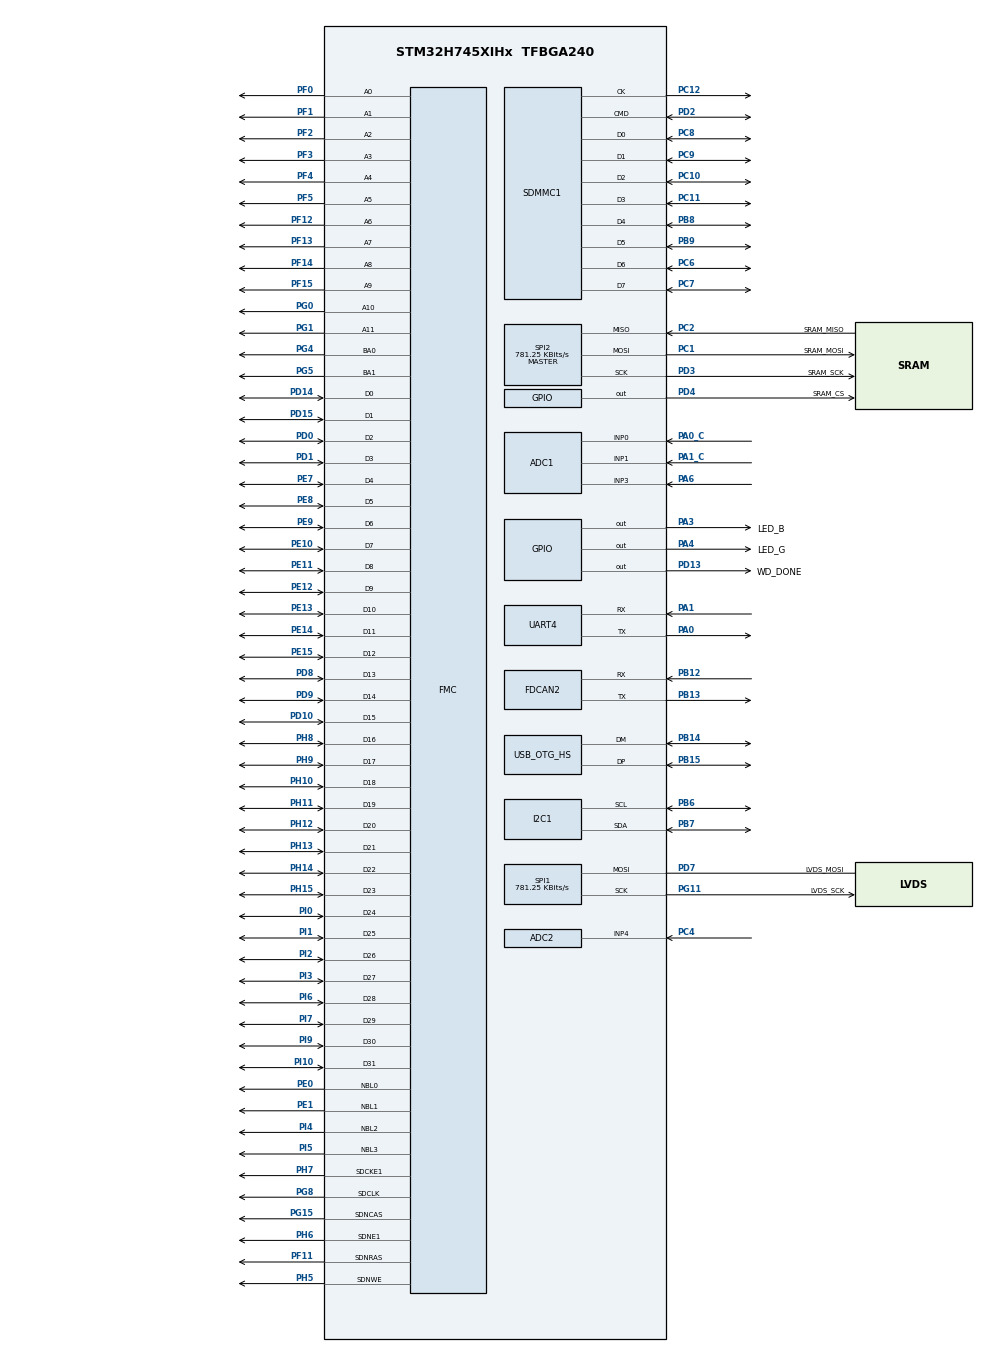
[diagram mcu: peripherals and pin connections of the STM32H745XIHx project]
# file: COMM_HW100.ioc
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ADC1.Channel-0\#ChannelRegularConversion=ADC_CHANNEL_0
ADC1.Channel-1\#ChannelRegularConversion=ADC_CHANNEL_1
ADC1.Channel-2\#ChannelRegularConversion=ADC_CHANNEL_3
ADC1.ContinuousConvMode=ENABLE
ADC1.NbrOfConversion=3
ADC1.NbrOfConversionFlag=1
ADC1.OffsetNumber-0\#ChannelRegularConversion=ADC_OFFSET_NONE
ADC1.OffsetNumber-1\#ChannelRegularConversion=ADC_OFFSET_NONE
ADC1.OffsetNumber-2\#ChannelRegularConversion=ADC_OFFSET_NONE
ADC1.OffsetSignedSaturation-0\#ChannelRegularConversion=DISABLE
ADC1.OffsetSignedSaturation-1\#ChannelRegularConversion=DISABLE
ADC1.OffsetSignedSaturation-2\#ChannelRegularConversion=DISABLE
ADC1.Overrun=ADC_OVR_DATA_OVERWRITTEN
ADC1.Rank-0\#ChannelRegularConversion=1
ADC1.Rank-1\#ChannelRegularConversion=2
ADC1.Rank-2\#ChannelRegularConversion=3
ADC1.SamplingTime-0\#ChannelRegularConversion=ADC_SAMPLETIME_1CYCLE_5
ADC1.SamplingTime-1\#ChannelRegularConversion=ADC_SAMPLETIME_1CYCLE_5
ADC1.SamplingTime-2\#ChannelRegularConversion=ADC_SAMPLETIME_1CYCLE_5
ADC1.master=1
ADC2.Channel-0\#ChannelRegularConversion=ADC_CHANNEL_4
ADC2.ContinuousConvMode=ENABLE
ADC2.NbrOfConversionFlag=1
ADC2.OffsetNumber-0\#ChannelRegularConversion=ADC_OFFSET_NONE
ADC2.OffsetSignedSaturation-0\#ChannelRegularConversion=DISABLE
ADC2.Overrun=ADC_OVR_DATA_OVERWRITTEN
ADC2.Rank-0\#ChannelRegularConversion=1
ADC2.SamplingTime-0\#ChannelRegularConversion=ADC_SAMPLETIME_1CYCLE_5
CORTEX_M7.Enable_Spec=__NULL
CORTEX_M7.MPU_Control=__NULL
CORTEX_M7.default_mode_Activation=1
CortexM4.IPs=BDMA,CORTEX_M4\:I,DMA,FATFS_M4\:I,FREERTOS_M4\:I,GPIO,IWDG2\:I,MDMA,NVIC2\:I,OPENAMP_M4\:I,PDM2PCM_M4\:I,PWR,RCC,RESMGR_UTILITY,SYS_M4\:I,USB_DEVICE_M4\:I,USB_HOST_M4\:I,VREFBUF,WWDG2\:I,DEBUG,FMC\:I
CortexM4.Pins=PD4
CortexM7.IPs=BDMA\:I,CORTEX_M7\:I,DMA\:I,FATFS_M7\:I,FREERTOS_M7\:I,GPIO\:I,IWDG1\:I,MDMA\:I,NVIC1\:I,OPENAMP_M7\:I,PDM2PCM_M7\:I,PWR\:I,RCC\:I,RESMGR_UTILITY\:I,SYS\:I,USB_DEVICE_M7\:I,USB_HOST_M7\:I,VREFBUF\:I,WWDG1\:I,MEMORYMAP\:I,DEBUG\:I,UART4\:I,FDCAN2\:I,I2C1\:I,ADC1\:I,ADC2\:I,SPI1\:I,SPI2\:I,SDMMC1\:I,TIM1\:I,USB_OTG_HS\:I
CortexM7.Pins=PD13,PA3,PA4
FDCAN2.CalculateBaudRateNominal=500000
FDCAN2.CalculateTimeBitNominal=2000
FDCAN2.CalculateTimeQuantumNominal=200.0
FDCAN2.ExtFiltersNbr=1
FDCAN2.NominalPrescaler=10
FDCAN2.NominalTimeSeg1=8
FDCAN2.RxFifo0ElmtsNbr=8
FDCAN2.TxFifoQueueElmtsNbr=8
FMC.CASLatency1=FMC_SDRAM_CAS_LATENCY_3
FMC.ExitSelfRefreshDelay1=7
FMC.LoadToActiveDelay1=2
FMC.RCDDelay1=2
FMC.RPDelay1=2
FMC.RPDelay2=2
FMC.ReadBurst1=FMC_SDRAM_RBURST_ENABLE
FMC.ReadPipeDelay1=FMC_SDRAM_RPIPE_DELAY_1
FMC.RowCycleDelay1=7
FMC.RowCycleDelay2=7
FMC.SDClockPeriod1=FMC_SDRAM_CLOCK_PERIOD_2
FMC.SelfRefreshTime1=4
FMC.WriteRecoveryTime1=3
I2C1.Timing=0x00909FCE
Mcu.Family=STM32H7
Mcu.Name=STM32H745XIHx
Mcu.Package=TFBGA240
NVIC1.FDCAN2_IT0_IRQn=true\:5\:0\:true\:false\:true\:true\:true\:true
NVIC1.OTG_HS_IRQn=true\:0\:0\:false\:false\:true\:false\:true\:true
NVIC1.PriorityGroup=NVIC_PRIORITYGROUP_4
NVIC1.TIM1_UP_IRQn=true\:15\:0\:false\:false\:true\:false\:true\:true
NVIC1.TimeBase=TIM1_UP_IRQn
NVIC1.TimeBaseIP=TIM1
NVIC1.UART4_IRQn=true\:0\:0\:false\:false\:true\:true\:true\:true
NVIC2.PriorityGroup=NVIC_PRIORITYGROUP_4
PA0.Mode=Asynchronous
PA0.PinAttribute=CortexM7
PA0.Signal=UART4_TX
PA0_C.PinAttribute=CortexM7
PA0_C.Signal=ADCx_INP0
PA1.Mode=Asynchronous
PA1.PinAttribute=CortexM7
PA1.Signal=UART4_RX
PA13\ (JTMS/SWDIO).Mode=Serial_Wire
PA13\ (JTMS/SWDIO).PinAttribute=CortexM7
PA13\ (JTMS/SWDIO).Signal=DEBUG_JTMS-SWDIO
PA14\ (JTCK/SWCLK).Mode=Serial_Wire
PA14\ (JTCK/SWCLK).PinAttribute=CortexM7
PA14\ (JTCK/SWCLK).Signal=DEBUG_JTCK-SWCLK
PA1_C.PinAttribute=CortexM7
PA1_C.Signal=ADCx_INP1
PA3.GPIO_Label=LED_B
PA3.PinAttribute=CortexM7
PA3.Signal=GPIO_Output
PA4.GPIO_Label=LED_G
PA4.PinAttribute=CortexM7
PA4.Signal=GPIO_Output
PA6.PinAttribute=CortexM7
PA6.Signal=ADCx_INP3
PB12.Mode=FDCAN_Activate
PB12.PinAttribute=CortexM7
PB12.Signal=FDCAN2_RX
PB13.Mode=FDCAN_Activate
PB13.PinAttribute=CortexM7
PB13.Signal=FDCAN2_TX
PB14.Mode=Device_Only_FS
PB14.PinAttribute=CortexM7
PB14.Signal=USB_OTG_HS_DM
PB15.Mode=Device_Only_FS
PB15.PinAttribute=CortexM7
PB15.Signal=USB_OTG_HS_DP
PB6.Mode=I2C
PB6.PinAttribute=CortexM7
PB6.Signal=I2C1_SCL
PB7.Mode=I2C
PB7.PinAttribute=CortexM7
PB7.Signal=I2C1_SDA
PB8.Mode=mmc_8_bits_Wide_bus
PB8.PinAttribute=CortexM7
PB8.Signal=SDMMC1_D4
PB9.Mode=mmc_8_bits_Wide_bus
PB9.PinAttribute=CortexM7
PB9.Signal=SDMMC1_D5
PC1.GPIO_Label=SRAM_MOSI
PC1.Mode=Full_Duplex_Master
PC1.PinAttribute=CortexM7
PC1.Signal=SPI2_MOSI
PC10.Mode=mmc_8_bits_Wide_bus
PC10.PinAttribute=CortexM7
PC10.Signal=SDMMC1_D2
PC11.Mode=mmc_8_bits_Wide_bus
PC11.PinAttribute=CortexM7
PC11.Signal=SDMMC1_D3
PC12.GPIO_Speed_High_Default=GPIO_SPEED_FREQ_VERY_HIGH
PC12.Mode=mmc_8_bits_Wide_bus
PC12.PinAttribute=CortexM7
PC12.Signal=SDMMC1_CK
PC14-OSC32_IN\ (OSC32_IN).Mode=LSE-External-Oscillator
PC14-OSC32_IN\ (OSC32_IN).PinAttribute=Free
PC14-OSC32_IN\ (OSC32_IN).Signal=RCC_OSC32_IN
PC15-OSC32_OUT\ (OSC32_OUT).Mode=LSE-External-Oscillator
PC15-OSC32_OUT\ (OSC32_OUT).PinAttribute=Free
PC15-OSC32_OUT\ (OSC32_OUT).Signal=RCC_OSC32_OUT
PC2.GPIO_Label=SRAM_MISO
PC2.Mode=Full_Duplex_Master
PC2.PinAttribute=CortexM7
PC2.Signal=SPI2_MISO
PC4.PinAttribute=CortexM7
PC4.Signal=ADCx_INP4
PC6.Mode=mmc_8_bits_Wide_bus
PC6.PinAttribute=CortexM7
PC6.Signal=SDMMC1_D6
PC7.Mode=mmc_8_bits_Wide_bus
PC7.PinAttribute=CortexM7
PC7.Signal=SDMMC1_D7
PC8.Mode=mmc_8_bits_Wide_bus
PC8.PinAttribute=CortexM7
PC8.Signal=SDMMC1_D0
PC9.Mode=mmc_8_bits_Wide_bus
PC9.PinAttribute=CortexM7
PC9.Signal=SDMMC1_D1
PD0.PinAttribute=CortexM4
PD0.Signal=FMC_D2_DA2
PD1.PinAttribute=CortexM4
PD1.Signal=FMC_D3_DA3
PD10.PinAttribute=CortexM4
PD10.Signal=FMC_D15_DA15
PD13.GPIO_Label=WD_DONE
PD13.GPIO_PuPd=GPIO_NOPULL
PD13.PinAttribute=CortexM7
PD13.PinState=GPIO_PIN_SET
PD13.Signal=GPIO_Output
PD14.PinAttribute=CortexM4
PD14.Signal=FMC_D0_DA0
PD15.PinAttribute=CortexM4
PD15.Signal=FMC_D1_DA1
PD2.Mode=mmc_8_bits_Wide_bus
PD2.PinAttribute=CortexM7
PD2.Signal=SDMMC1_CMD
PD3.GPIO_Label=SRAM_SCK
PD3.Mode=Full_Duplex_Master
PD3.PinAttribute=CortexM7
PD3.Signal=SPI2_SCK
PD4.GPIO_Label=SRAM_CS
PD4.PinAttribute=CortexM4
PD4.PinState=GPIO_PIN_SET
PD4.Signal=GPIO_Output
PD7.GPIO_Label=LVDS_MOSI
PD7.Mode=Simplex_Bidirectional_Master
PD7.PinAttribute=CortexM7
PD7.Signal=SPI1_MOSI
PD8.PinAttribute=CortexM4
PD8.Signal=FMC_D13_DA13
PD9.PinAttribute=CortexM4
PD9.Signal=FMC_D14_DA14
PE0.PinAttribute=CortexM4
PE0.Signal=FMC_NBL0
PE1.PinAttribute=CortexM4
PE1.Signal=FMC_NBL1
PE10.PinAttribute=CortexM4
PE10.Signal=FMC_D7_DA7
PE11.PinAttribute=CortexM4
PE11.Signal=FMC_D8_DA8
PE12.PinAttribute=CortexM4
PE12.Signal=FMC_D9_DA9
PE13.PinAttribute=CortexM4
PE13.Signal=FMC_D10_DA10
PE14.PinAttribute=CortexM4
PE14.Signal=FMC_D11_DA11
PE15.PinAttribute=CortexM4
PE15.Signal=FMC_D12_DA12
PE7.PinAttribute=CortexM4
PE7.Signal=FMC_D4_DA4
PE8.PinAttribute=CortexM4
PE8.Signal=FMC_D5_DA5
PE9.PinAttribute=CortexM4
PE9.Signal=FMC_D6_DA6
PF0.PinAttribute=CortexM4
PF0.Signal=FMC_A0
PF1.PinAttribute=CortexM4
PF1.Signal=FMC_A1
PF11.PinAttribute=CortexM4
PF11.Signal=FMC_SDNRAS
PF12.PinAttribute=CortexM4
PF12.Signal=FMC_A6
PF13.PinAttribute=CortexM4
PF13.Signal=FMC_A7
PF14.PinAttribute=CortexM4
PF14.Signal=FMC_A8
PF15.PinAttribute=CortexM4
PF15.Signal=FMC_A9
PF2.PinAttribute=CortexM4
PF2.Signal=FMC_A2
PF3.PinAttribute=CortexM4
PF3.Signal=FMC_A3
PF4.PinAttribute=CortexM4
PF4.Signal=FMC_A4
PF5.PinAttribute=CortexM4
PF5.Signal=FMC_A5
PG0.PinAttribute=CortexM4
PG0.Signal=FMC_A10
PG1.PinAttribute=CortexM4
PG1.Signal=FMC_A11
PG11.GPIO_Label=LVDS_SCK
PG11.Mode=Simplex_Bidirectional_Master
PG11.PinAttribute=CortexM7
PG11.Signal=SPI1_SCK
PG15.PinAttribute=CortexM4
PG15.Signal=FMC_SDNCAS
PG4.PinAttribute=CortexM4
PG4.Signal=FMC_A14_BA0
PG5.PinAttribute=CortexM4
PG5.Signal=FMC_A15_BA1
PG8.PinAttribute=CortexM4
PG8.Signal=FMC_SDCLK
PH0-OSC_IN\ (PH0).Mode=HSE-External-Oscillator
PH0-OSC_IN\ (PH0).PinAttribute=Free
PH0-OSC_IN\ (PH0).Signal=RCC_OSC_IN
PH1-OSC_OUT\ (PH1).Mode=HSE-External-Oscillator
PH1-OSC_OUT\ (PH1).PinAttribute=Free
PH1-OSC_OUT\ (PH1).Signal=RCC_OSC_OUT
PH10.PinAttribute=CortexM4
PH10.Signal=FMC_D18
PH11.PinAttribute=CortexM4
PH11.Signal=FMC_D19
PH12.PinAttribute=CortexM4
PH12.Signal=FMC_D20
PH13.PinAttribute=CortexM4
PH13.Signal=FMC_D21
PH14.PinAttribute=CortexM4
PH14.Signal=FMC_D22
PH15.PinAttribute=CortexM4
PH15.Signal=FMC_D23
PH5.PinAttribute=CortexM4
PH5.Signal=FMC_SDNWE
PH6.Mode=SdramChipSelect2_1
PH6.PinAttribute=CortexM4
PH6.Signal=FMC_SDNE1
PH7.Mode=SdramChipSelect2_1
PH7.PinAttribute=CortexM4
PH7.Signal=FMC_SDCKE1
PH8.PinAttribute=CortexM4
PH8.Signal=FMC_D16
PH9.PinAttribute=CortexM4
PH9.Signal=FMC_D17
PI0.PinAttribute=CortexM4
PI0.Signal=FMC_D24
PI1.PinAttribute=CortexM4
PI1.Signal=FMC_D25
PI10.PinAttribute=CortexM4
PI10.Signal=FMC_D31
PI2.PinAttribute=CortexM4
PI2.Signal=FMC_D26
PI3.PinAttribute=CortexM4
PI3.Signal=FMC_D27
PI4.PinAttribute=CortexM4
PI4.Signal=FMC_NBL2
PI5.PinAttribute=CortexM4
PI5.Signal=FMC_NBL3
PI6.PinAttribute=CortexM4
PI6.Signal=FMC_D28
PI7.PinAttribute=CortexM4
PI7.Signal=FMC_D29
PI9.PinAttribute=CortexM4
PI9.Signal=FMC_D30
ProjectManager.HeapSize=M4-0x200,M7-0x200
ProjectManager.StackSize=M4-0x400,M7-0x400
ProjectManager.TargetToolchain=STM32CubeIDE
RCC.ADCFreq_Value=50000000
RCC.APB1Freq_Value=37500000
RCC.APB2Freq_Value=75000000
RCC.APB3Freq_Value=75000000
RCC.APB4Freq_Value=75000000
RCC.CortexFreq_Value=75000000
RCC.D2PPRE1=RCC_APB1_DIV2
RCC.DIVM1=2
RCC.DIVM2=2
RCC.DIVN1=12
RCC.DIVN2=12
RCC.DIVP2=3
RCC.DIVQ1=3
RCC.HCLKFreq_Value=75000000
RCC.PLL2FRACN=0
RCC.PLL3FRACN=0
RCC.PLLFRACN=0
RCC.PLLSourceVirtual=RCC_PLLSOURCE_HSE
RCC.SYSCLKFreq_VALUE=75000000
RCC.SYSCLKSource=RCC_SYSCLKSOURCE_PLLCLK
RCC.SupplySource=PWR_LDO_SUPPLY
RCC.USBFreq_Value=50000000
SDMMC1.ClockDiv=8
SH.ADCx_INP0.0=ADC1_INP0,IN0-Single-Ended
SH.ADCx_INP1.0=ADC1_INP1,IN1-Single-Ended
SH.ADCx_INP3.0=ADC1_INP3,IN3-Single-Ended
SH.ADCx_INP4.0=ADC2_INP4,IN4-Single-Ended
SH.FMC_A0.0=FMC_A0,12b-sda1
SH.FMC_A1.0=FMC_A1,12b-sda1
SH.FMC_A10.0=FMC_A10,12b-sda1
SH.FMC_A11.0=FMC_A11,12b-sda1
SH.FMC_A14_BA0.0=FMC_BA0,FourSdramBanks1
SH.FMC_A15_BA1.0=FMC_BA1,FourSdramBanks1
SH.FMC_A2.0=FMC_A2,12b-sda1
SH.FMC_A3.0=FMC_A3,12b-sda1
SH.FMC_A4.0=FMC_A4,12b-sda1
SH.FMC_A5.0=FMC_A5,12b-sda1
SH.FMC_A6.0=FMC_A6,12b-sda1
SH.FMC_A7.0=FMC_A7,12b-sda1
SH.FMC_A8.0=FMC_A8,12b-sda1
SH.FMC_A9.0=FMC_A9,12b-sda1
SH.FMC_D0_DA0.0=FMC_D0,sd-32b-d1
SH.FMC_D10_DA10.0=FMC_D10,sd-32b-d1
SH.FMC_D11_DA11.0=FMC_D11,sd-32b-d1
SH.FMC_D12_DA12.0=FMC_D12,sd-32b-d1
SH.FMC_D13_DA13.0=FMC_D13,sd-32b-d1
SH.FMC_D14_DA14.0=FMC_D14,sd-32b-d1
SH.FMC_D15_DA15.0=FMC_D15,sd-32b-d1
SH.FMC_D16.0=FMC_D16,sd-32b-d1
SH.FMC_D17.0=FMC_D17,sd-32b-d1
SH.FMC_D18.0=FMC_D18,sd-32b-d1
SH.FMC_D19.0=FMC_D19,sd-32b-d1
SH.FMC_D1_DA1.0=FMC_D1,sd-32b-d1
SH.FMC_D20.0=FMC_D20,sd-32b-d1
SH.FMC_D21.0=FMC_D21,sd-32b-d1
SH.FMC_D22.0=FMC_D22,sd-32b-d1
SH.FMC_D23.0=FMC_D23,sd-32b-d1
SH.FMC_D24.0=FMC_D24,sd-32b-d1
SH.FMC_D25.0=FMC_D25,sd-32b-d1
SH.FMC_D26.0=FMC_D26,sd-32b-d1
SH.FMC_D27.0=FMC_D27,sd-32b-d1
SH.FMC_D28.0=FMC_D28,sd-32b-d1
SH.FMC_D29.0=FMC_D29,sd-32b-d1
SH.FMC_D2_DA2.0=FMC_D2,sd-32b-d1
SH.FMC_D30.0=FMC_D30,sd-32b-d1
SH.FMC_D31.0=FMC_D31,sd-32b-d1
SH.FMC_D3_DA3.0=FMC_D3,sd-32b-d1
SH.FMC_D4_DA4.0=FMC_D4,sd-32b-d1
SH.FMC_D5_DA5.0=FMC_D5,sd-32b-d1
SH.FMC_D6_DA6.0=FMC_D6,sd-32b-d1
SH.FMC_D7_DA7.0=FMC_D7,sd-32b-d1
SH.FMC_D8_DA8.0=FMC_D8,sd-32b-d1
SH.FMC_D9_DA9.0=FMC_D9,sd-32b-d1
SH.FMC_NBL0.0=FMC_NBL0,Sd4ByteEnable1
SH.FMC_NBL1.0=FMC_NBL1,Sd4ByteEnable1
SH.FMC_NBL2.0=FMC_NBL2,Sd4ByteEnable1
SH.FMC_NBL3.0=FMC_NBL3,Sd4ByteEnable1
SH.FMC_SDCLK.0=FMC_SDCLK,12b-sda1
SH.FMC_SDNCAS.0=FMC_SDNCAS,12b-sda1
SH.FMC_SDNRAS.0=FMC_SDNRAS,12b-sda1
SH.FMC_SDNWE.0=FMC_SDNWE,12b-sda1
SPI1.BaudRatePrescaler=SPI_BAUDRATEPRESCALER_64
SPI1.CalculateBaudRate=781.25 KBits/s
SPI1.DataSize=SPI_DATASIZE_8BIT
SPI1.Direction=SPI_DIRECTION_1LINE
SPI1.Mode=SPI_MODE_MASTER
SPI1.VirtualType=VM_MASTER
SPI2.BaudRatePrescaler=SPI_BAUDRATEPRESCALER_64
SPI2.CalculateBaudRate=781.25 KBits/s
SPI2.DataSize=SPI_DATASIZE_8BIT
SPI2.Direction=SPI_DIRECTION_2LINES
SPI2.Mode=SPI_MODE_MASTER
SPI2.VirtualType=VM_MASTER
SYS.userName=SYS_M7
USB_DEVICE_M7.CLASS_NAME_HS=CDC
USB_DEVICE_M7.VirtualMode-CDC_HS=Cdc
USB_DEVICE_M7.VirtualModeHS=Cdc_HS
USB_OTG_HS.VirtualMode-Device_Only_FS=Device_Only_FS
VP_MEMORYMAP_VS_MEMORYMAP.Mode=CurAppReg
VP_SYS_M4_VS_Systick.Mode=SysTick
VP_SYS_VS_tim1.Mode=TIM1
VP_USB_DEVICE_M7_VS_USB_DEVICE_CDC_HS.Mode=CDC_HS
board=custom

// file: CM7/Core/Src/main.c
/* USER CODE BEGIN Header */
/**
  ******************************************************************************
  * @file           : main.c
  * @brief          : Main program body
  ******************************************************************************
  * @attention
  *
  * Copyright (c) 2025 STMicroelectronics.
  * All rights reserved.
  *
  * This software is licensed under terms that can be found in the LICENSE file
  * in the root directory of this software component.
  * If no LICENSE file comes with this software, it is provided AS-IS.
  *
  ******************************************************************************
  */
/* USER CODE END Header */
#include "main.h"
#include "usb_device.h"

/* USER CODE BEGIN Includes */
#include "FreeRTOS.h"
#include "queue.h"
#include "semphr.h"
#include "task.h"
#include "timers.h"

#include "ff.h"
#include "diskio.h"

#include "usb_device.h"
#include "usbd_cdc_if.h"
#include "uart_driver.h"

#include "cli_setup.h"
#include "cdc_driver.h"

#include "can.h"
#include "adc_driver.h"

#include "queuex.h"
#include "tcpip.h"
#include "dhcpserver.h"
#include "telnet.h"

#include "IS66WVS4M8BLL.h"

#include "cli_setup.h"

/* USER CODE END Includes */

/* USER CODE BEGIN PD */

/* DUAL_CORE_BOOT_SYNC_SEQUENCE: Define for dual core boot synchronization    */
/*                             demonstration code based on hardware semaphore */
/* This define is present in both CM7/CM4 projects                            */
/* To comment when developping/debugging on a single core                     */
//#define DUAL_CORE_BOOT_SYNC_SEQUENCE

#if defined(DUAL_CORE_BOOT_SYNC_SEQUENCE)
#ifndef HSEM_ID_0
#define HSEM_ID_0 (0U) /* HW semaphore 0*/
#endif
#endif /* DUAL_CORE_BOOT_SYNC_SEQUENCE */

/* USER CODE END PD */

FDCAN_HandleTypeDef hfdcan2;

MMC_HandleTypeDef hmmc1;

/* USER CODE BEGIN PV */
uint32_t server_received = 0;
volatile TaskHandle_t sWdTask = NULL;
//IS66_t IS66WV = {
//    .spi = SPI2,
//    .cs_port = SRAM_CS_GPIO_Port,
//    .cs_pin = SRAM_CS_Pin,
//    .remain_size = 0,
//    .transfer_done = 0,
//    .dma = DMA1,
//    .dma_stream_tx = LL_DMA_STREAM_0, // Stream 0 cho TX
//    .dma_stream_rx = LL_DMA_STREAM_1, // Stream 1 cho RX
//    .dma_channel = LL_DMAMUX_CHANNEL_1 // Channel 1 chung
//};

queue_handle_t tcpQueue;
queue_handle_t usbQueue;

/* USER CODE END PV */

void SystemClock_Config(void);
void PeriphCommonClock_Config(void);
static void MX_GPIO_Init(void);
static void MX_UART4_Init(void);
static void MX_FDCAN2_Init(void);
static void MX_I2C1_Init(void);
static void MX_ADC1_Init(void);
static void MX_ADC2_Init(void);
static void MX_SPI1_Init(void);
static void MX_SPI2_Init(void);
static void MX_SDMMC1_MMC_Init(void);

/* USER CODE BEGIN 0 */
static void blink( void * parameters )
{
    LL_GPIO_SetOutputPin(LED_G_GPIO_Port, LED_G_Pin);
    for( ; ; )
    {
	    LL_GPIO_ResetOutputPin(WD_DONE_GPIO_Port, WD_DONE_Pin);
	    vTaskDelay(pdMS_TO_TICKS(200));
	    LL_GPIO_SetOutputPin(WD_DONE_GPIO_Port, WD_DONE_Pin);
	    vTaskDelay(pdMS_TO_TICKS(600));

	    LL_GPIO_ResetOutputPin(LED_B_GPIO_Port, LED_B_Pin);
	    vTaskDelay(pdMS_TO_TICKS(300));
	    LL_GPIO_SetOutputPin(LED_B_GPIO_Port, LED_B_Pin);
	    vTaskDelay(pdMS_TO_TICKS(1000));
    }
}

static void CLI_Polling_Task( void * parameters )
{
    ( void ) parameters;

    for( ; ; )
    {
        uint8_t rxData;
        if (CDC_getRxReady())
        {
            while (CDC_RX_RingBuffer_Get(&rxData))
            {
                embeddedCliReceiveChar(get_COMM_USB_CliPointer(), (char)rxData);
            }
            embeddedCliProcess(get_COMM_USB_CliPointer());
            CDC_setRxReady(0);
        }

        if (UART_Driver_IsDataAvailable(UART4))
        {
        	rxData = UART_Driver_Read(UART4);
            embeddedCliReceiveChar(get_COMM_UART_CliPointer(), (char)rxData);
            embeddedCliProcess(get_COMM_UART_CliPointer());
        }

        vTaskDelay(1);
    }
}

static void USB_HS_Task( void * parameters )
{
    ( void ) parameters;

    for( ; ; )
    {
    	if (USB_checkUSB())
    	{
    		USB_setCheckFlag(0);
    	    uint8_t comPortState = CDC_ComPort_IsOpen() ? 1 : 0;
    	    if(comPortState){
    	    	LL_GPIO_ResetOutputPin(LED_B_GPIO_Port, LED_B_Pin);
    	    	char msg[] = "---COMM USB CLI HELLO---\r\n";
    	    	CDC_Transmit_HS((uint8_t*)msg, strlen(msg));
    	    } else {
    	    	LL_GPIO_SetOutputPin(LED_B_GPIO_Port, LED_B_Pin);
    	    }
    	}
        vTaskDelay( 100 ); /* delay 100 ticks */
    }
}
//
//static void USB_FS_Task( void * parameters )
//{
//    ( void ) parameters;
//
//    for( ; ; )
//    {
//    	if (USB_checkUSB())
//    	{
//    		USB_setCheckFlag(0);
//    	    uint8_t comPortState = CDC_ComPort_IsOpen() ? 1 : 0;
//    	    if(comPortState){
//    	    	LL_GPIO_ResetOutputPin(LED_B_GPIO_Port, LED_B_Pin);
//    	    	char msg[] = "---COMM USB CLI HELLO---\r\n";
//    	    	CDC_Transmit_FS((uint8_t*)msg, strlen(msg));
//    	    } else {
//    	    	LL_GPIO_SetOutputPin(LED_B_GPIO_Port, LED_B_Pin);
//    	    }
//    	}
//        vTaskDelay( 100 ); /* delay 100 ticks */
//    }
//}
//

static void UsbInitTask(void *pv)
{
	usb_init();
    for(;;)
    {
       queue_manager( &tcpQueue );
       queue_manager( &usbQueue );
       vTaskDelay(1);
    }
}

extern csp_conf_t csp_conf;
extern csp_iface_t can_iface;

FDCAN_TxHeaderTypeDef txHeader;
uint8_t txData[8];
uint32_t txBufferIndex = 0;

void csp_tx_task(void *argument) {

	const char *msg = "hello";
	for(;;)
	{
		csp_conn_t *conn = csp_connect(CSP_PRIO_NORM, 2, 10, 1000, CSP_O_NONE);
		if (conn == NULL) {
			vTaskDelay(1000);
			continue;
		}

		/* Cấp packet và copy payload */
		size_t len = strlen(msg);
		csp_packet_t *pkt = csp_buffer_get(len);
		if (pkt == NULL) {
			csp_close(conn);
			vTaskDelay(1000);
			continue;
		}

		memcpy(pkt->data, msg, len);
		pkt->length = len;

		/* Gửi packet, nếu lỗi thì phải free buffer */
		if (csp_send(conn, pkt, 1000 /*ms*/) == CSP_ERR_NONE) {
			csp_buffer_free(pkt);
		}

		/* Đóng kết nối */
		csp_close(conn);

		vTaskDelay(2000);
	}
}

void csp_rx_task(void *argument) {
	/* Create socket with no specific socket options, e.g. accepts CRC32, HMAC, XTEA, etc. if enabled during compilation */
	csp_socket_t *sock = csp_socket(CSP_SO_NONE);

	/* Bind socket to all ports, e.g. all incoming connections will be handled here */
	csp_bind(sock, CSP_ANY);

	/* Create a backlog of 10 connections, i.e. up to 10 new connections can be queued */
	csp_listen(sock, 10);

	/* Wait for connections and then process packets on the connection */
	while (1) {
		/* Wait for a new connection, 1000 mS timeout */
		csp_conn_t *conn;
		if ((conn = csp_accept(sock, 1000)) == NULL) {
			/* timeout */
			continue;
		}

		/* Read packets on connection, timout is 100 mS */
		csp_packet_t *packet;
		while ((packet = csp_read(conn, 100)) != NULL) {
			switch (csp_conn_dport(conn)) {
			case 8:
			case 7:

				if ((packet->data[0] & 0xF0)== 0x00/* 0x00 */) {

				}
				else if ((packet->data[0] & 0xF0)== 0x10/* 0x01 */) {

//					if ((packet->data[0] & 0x0F) == 0x06) {

					if(packet->data[1]== 0x04) {
						size_t len = 6;
						csp_packet_t *reply = csp_buffer_get(sizeof(len));
						reply->data[0]= packet->data[0]&0x0F;
						reply->data[1]= packet->data[1];
						reply->data[2]= 0x00;
						reply->data[3]= 0x00;
						reply->data[4]= 0x00;
						reply->data[5]= 0x18;
						reply->length= 6;

						if (csp_send(conn, reply, 1000) == CSP_ERR_NONE)
						csp_buffer_free(reply);

						break;
					}

					uint16_t raw= ADC1_ReadIndex(packet->data[1]);
					int32_t temperature = ((raw* 3300)- (500* 65535))/ 65535;
					if(temperature > 1250) {
						temperature = 1250;
					} else if(temperature < -400) {
						temperature = -400;
					}

					csp_packet_t *reply = csp_buffer_get(sizeof(temperature));
					reply->data[0]= packet->data[0]&0x0F;
					reply->data[1]= packet->data[1];
					reply->data[2]= (uint8_t)((temperature>> 24)& 0xFF);
					reply->data[3]= (uint8_t)((temperature>> 16)& 0xFF);
					reply->data[4]= (uint8_t)((temperature>> 8)& 0xFF);
					reply->data[5]= (uint8_t)(temperature& 0xFF);
					reply->length= 6;

//				        if (reply) {
//				            memcpy(reply->data, &temperature, sizeof(temperature));
//				            reply->length = sizeof(temperature);

					if (csp_send(conn, reply, 1000) == CSP_ERR_NONE)
					csp_buffer_free(reply);
//						}
//					}
				}

				/* Process packet here */
				csp_log_info("Packet received on MY_SERVER_PORT: %s", (char *) packet->data);

				char out[128];
				snprintf(out, sizeof(out),
				         "RxData from node %u port %u: %.*s",
				         csp_conn_src(conn),
				         csp_conn_dport(conn),
				         packet->length,
				         (char *)packet->data);

				embeddedCliPrint(get_COMM_UART_CliPointer(), out);

				csp_buffer_free(packet);
				++server_received;
				break;

			default:
//				/* Call the default CSP service handler, handle pings, buffer use, etc. */
////				csp_service_handler(conn, packet);
//
//				snprintf(out, sizeof(out),
//				         "RxData from node %u port %u: %.*s",
//				         csp_conn_src(conn),
//				         csp_conn_dport(conn),
//				         packet->length,
//				         (char *)packet->data);
//
//				embeddedCliPrint(get_COMM_UART_CliPointer(), out);
				csp_buffer_free(packet);
//
				break;
			}
		}
		/* Close current connection */
		csp_close(conn);

		vTaskDelay(100);
	}
}

/* USER CODE END 0 */

int main(void)
{

/* USER CODE BEGIN Boot_Mode_Sequence_0 */
#if defined(DUAL_CORE_BOOT_SYNC_SEQUENCE)
  int32_t timeout;
#endif /* DUAL_CORE_BOOT_SYNC_SEQUENCE */
/* USER CODE END Boot_Mode_Sequence_0 */

/* USER CODE BEGIN Boot_Mode_Sequence_1 */
#if defined(DUAL_CORE_BOOT_SYNC_SEQUENCE)
  /* Wait until CPU2 boots and enters in stop mode or timeout*/
  timeout = 0xFFFF;
  while((__HAL_RCC_GET_FLAG(RCC_FLAG_D2CKRDY) != RESET) && (timeout-- > 0));
  if ( timeout < 0 )
  {
  Error_Handler();
  }
#endif /* DUAL_CORE_BOOT_SYNC_SEQUENCE */
/* USER CODE END Boot_Mode_Sequence_1 */
  /* MCU Configuration--------------------------------------------------------*/

  /* Reset of all peripherals, Initializes the Flash interface and the Systick. */
  HAL_Init();

  /* Configure the system clock */
  SystemClock_Config();

  /* Configure the peripherals common clocks */
  PeriphCommonClock_Config();
/* USER CODE BEGIN Boot_Mode_Sequence_2 */
#if defined(DUAL_CORE_BOOT_SYNC_SEQUENCE)
/* When system initialization is finished, Cortex-M7 will release Cortex-M4 by means of
HSEM notification */
/*HW semaphore Clock enable*/
__HAL_RCC_HSEM_CLK_ENABLE();
/*Take HSEM */
HAL_HSEM_FastTake(HSEM_ID_0);
/*Release HSEM in order to notify the CPU2(CM4)*/
HAL_HSEM_Release(HSEM_ID_0,0);
/* wait until CPU2 wakes up from stop mode */
timeout = 0xFFFF;
while((__HAL_RCC_GET_FLAG(RCC_FLAG_D2CKRDY) == RESET) && (timeout-- > 0));
if ( timeout < 0 )
{
Error_Handler();
}
#endif /* DUAL_CORE_BOOT_SYNC_SEQUENCE */
/* USER CODE END Boot_Mode_Sequence_2 */

  /* Initialize all configured peripherals */
  MX_GPIO_Init();
  MX_UART4_Init();
  MX_FDCAN2_Init();
  MX_I2C1_Init();
  MX_ADC1_Init();
  MX_ADC2_Init();
  MX_SPI1_Init();
  MX_SPI2_Init();
  MX_SDMMC1_MMC_Init();
//  MX_USB_DEVICE_Init();
  /* USER CODE BEGIN 2 */

  CDC_RingBuffer_Init();
  UART_Driver_Init();
  SystemCLI_Init();

  /*CSP INIT*/
  csp_conf_get_defaults(&csp_conf);
  csp_conf.address = 12;
  csp_init(&csp_conf);
  /*CSP INTERFACE INIT*/
  can_csp_init();
  csp_route_start_task(500, 6);
  csp_rtable_set(3, CSP_ID_HOST_SIZE, &can_iface, CSP_NO_VIA_ADDRESS);
  csp_rtable_set(2, CSP_ID_HOST_SIZE, &can_iface, CSP_NO_VIA_ADDRESS);
  csp_rtable_set(1, CSP_ID_HOST_SIZE, &can_iface, CSP_NO_VIA_ADDRESS);
//  SRAM_Initialize(&IS66WV);

  tcpip_init();
  telnet_server_init();

  // Set the queue on the tcpip stack io
  tcpQueue.messageDirection  = TCP_TO_USB;
  tcpQueue.output            = usb_output;
  queue_init(&tcpQueue);

  // Set the queue on the usb io
  usbQueue.messageDirection   = USB_TO_TCP;
  usbQueue.output             = tcpip_output;
  queue_init(&usbQueue);

  xTaskCreate(UsbInitTask,		"USB_Init",				configMINIMAL_STACK_SIZE * 10, 	NULL, configMAX_PRIORITIES - 3U, NULL);
  xTaskCreate(blink,			"Blink",				configMINIMAL_STACK_SIZE * 10, 	NULL, configMAX_PRIORITIES - 3U, NULL);
  xTaskCreate(CLI_Polling_Task, "CLI_Polling_Task",		configMINIMAL_STACK_SIZE * 10, 	NULL, configMAX_PRIORITIES - 1U, NULL);
//  xTaskCreate(USB_HS_Task,		"USB_HS_Task",			configMINIMAL_STACK_SIZE * 10, 	NULL, configMAX_PRIORITIES - 3U, NULL);
//  xTaskCreate(USB_FS_Task,		"USB_FS_Task",			configMINIMAL_STACK_SIZE * 10, 	NULL, configMAX_PRIORITIES - 3U, NULL);
//  xTaskCreate(csp_tx_task, 		"csp_can_tx", 			configMINIMAL_STACK_SIZE * 10, 	NULL, configMAX_PRIORITIES - 3U, NULL);
//  xTaskCreate(csp_rx_task, 		"csp_can_rx", 			configMINIMAL_STACK_SIZE * 10, 	NULL, configMAX_PRIORITIES - 1U, NULL);

  vTaskStartScheduler();
  /* USER CODE END 2 */

  /* Infinite loop */
  while (1)
  {

  }
}

void SystemClock_Config(void)
{
  RCC_OscInitTypeDef RCC_OscInitStruct = {0};
  RCC_ClkInitTypeDef RCC_ClkInitStruct = {0};

  /** Supply configuration update enable
  */
  HAL_PWREx_ConfigSupply(PWR_LDO_SUPPLY);

  /** Configure the main internal regulator output voltage
  */
  __HAL_PWR_VOLTAGESCALING_CONFIG(PWR_REGULATOR_VOLTAGE_SCALE3);

  while(!__HAL_PWR_GET_FLAG(PWR_FLAG_VOSRDY)) {}

  /** Initializes the RCC Oscillators according to the specified parameters
  * in the RCC_OscInitTypeDef structure.
  */
  RCC_OscInitStruct.OscillatorType = RCC_OSCILLATORTYPE_HSE;
  RCC_OscInitStruct.HSEState = RCC_HSE_ON;
  RCC_OscInitStruct.PLL.PLLState = RCC_PLL_ON;
  RCC_OscInitStruct.PLL.PLLSource = RCC_PLLSOURCE_HSE;
  RCC_OscInitStruct.PLL.PLLM = 2;
  RCC_OscInitStruct.PLL.PLLN = 12;
  RCC_OscInitStruct.PLL.PLLP = 2;
  RCC_OscInitStruct.PLL.PLLQ = 3;
  RCC_OscInitStruct.PLL.PLLR = 2;
  RCC_OscInitStruct.PLL.PLLRGE = RCC_PLL1VCIRANGE_3;
  RCC_OscInitStruct.PLL.PLLVCOSEL = RCC_PLL1VCOMEDIUM;
  RCC_OscInitStruct.PLL.PLLFRACN = 0;
  if (HAL_RCC_OscConfig(&RCC_OscInitStruct) != HAL_OK)
  {
    Error_Handler();
  }

  /** Initializes the CPU, AHB and APB buses clocks
  */
  RCC_ClkInitStruct.ClockType = RCC_CLOCKTYPE_HCLK|RCC_CLOCKTYPE_SYSCLK
                              |RCC_CLOCKTYPE_PCLK1|RCC_CLOCKTYPE_PCLK2
                              |RCC_CLOCKTYPE_D3PCLK1|RCC_CLOCKTYPE_D1PCLK1;
  RCC_ClkInitStruct.SYSCLKSource = RCC_SYSCLKSOURCE_PLLCLK;
  RCC_ClkInitStruct.SYSCLKDivider = RCC_SYSCLK_DIV1;
  RCC_ClkInitStruct.AHBCLKDivider = RCC_HCLK_DIV1;
  RCC_ClkInitStruct.APB3CLKDivider = RCC_APB3_DIV1;
  RCC_ClkInitStruct.APB1CLKDivider = RCC_APB1_DIV2;
  RCC_ClkInitStruct.APB2CLKDivider = RCC_APB2_DIV1;
  RCC_ClkInitStruct.APB4CLKDivider = RCC_APB4_DIV1;

  if (HAL_RCC_ClockConfig(&RCC_ClkInitStruct, FLASH_LATENCY_1) != HAL_OK)
  {
    Error_Handler();
  }
}

void PeriphCommonClock_Config(void)
{
  RCC_PeriphCLKInitTypeDef PeriphClkInitStruct = {0};

  /** Initializes the peripherals clock
  */
  PeriphClkInitStruct.PeriphClockSelection = RCC_PERIPHCLK_ADC;
  PeriphClkInitStruct.PLL2.PLL2M = 2;
  PeriphClkInitStruct.PLL2.PLL2N = 12;
  PeriphClkInitStruct.PLL2.PLL2P = 3;
  PeriphClkInitStruct.PLL2.PLL2Q = 2;
  PeriphClkInitStruct.PLL2.PLL2R = 2;
  PeriphClkInitStruct.PLL2.PLL2RGE = RCC_PLL2VCIRANGE_3;
  PeriphClkInitStruct.PLL2.PLL2VCOSEL = RCC_PLL2VCOMEDIUM;
  PeriphClkInitStruct.PLL2.PLL2FRACN = 0;
  PeriphClkInitStruct.AdcClockSelection = RCC_ADCCLKSOURCE_PLL2;
  if (HAL_RCCEx_PeriphCLKConfig(&PeriphClkInitStruct) != HAL_OK)
  {
    Error_Handler();
  }
}

static void MX_ADC1_Init(void)
{

  LL_ADC_InitTypeDef ADC_InitStruct = {0};
  LL_ADC_REG_InitTypeDef ADC_REG_InitStruct = {0};
  LL_ADC_CommonInitTypeDef ADC_CommonInitStruct = {0};

  LL_GPIO_InitTypeDef GPIO_InitStruct = {0};

  /* Peripheral clock enable */
  LL_AHB1_GRP1_EnableClock(LL_AHB1_GRP1_PERIPH_ADC12);

  LL_AHB4_GRP1_EnableClock(LL_AHB4_GRP1_PERIPH_GPIOA);
  /**ADC1 GPIO Configuration
  PA6   ------> ADC1_INP3
  PA0_C   ------> ADC1_INP0
  PA1_C   ------> ADC1_INP1
  */
  GPIO_InitStruct.Pin = LL_GPIO_PIN_6;
  GPIO_InitStruct.Mode = LL_GPIO_MODE_ANALOG;
  GPIO_InitStruct.Pull = LL_GPIO_PULL_NO;
  LL_GPIO_Init(GPIOA, &GPIO_InitStruct);

  LL_SYSCFG_OpenAnalogSwitch(LL_SYSCFG_ANALOG_SWITCH_PA0|LL_SYSCFG_ANALOG_SWITCH_PA1);

  /** Common config
  */
  LL_ADC_SetOverSamplingScope(ADC1, LL_ADC_OVS_DISABLE);
  ADC_InitStruct.Resolution = LL_ADC_RESOLUTION_16B;
  ADC_InitStruct.LowPowerMode = LL_ADC_LP_MODE_NONE;
  ADC_InitStruct.LeftBitShift = LL_ADC_LEFT_BIT_SHIFT_NONE;
  LL_ADC_Init(ADC1, &ADC_InitStruct);
  ADC_REG_InitStruct.TriggerSource = LL_ADC_REG_TRIG_SOFTWARE;
  ADC_REG_InitStruct.SequencerLength = LL_ADC_REG_SEQ_SCAN_ENABLE_3RANKS;
  ADC_REG_InitStruct.SequencerDiscont = DISABLE;
  ADC_REG_InitStruct.ContinuousMode = LL_ADC_REG_CONV_CONTINUOUS;
  ADC_REG_InitStruct.Overrun = LL_ADC_REG_OVR_DATA_OVERWRITTEN;
  LL_ADC_REG_Init(ADC1, &ADC_REG_InitStruct);
  LL_ADC_REG_SetDataTransferMode(ADC1, LL_ADC_REG_DR_TRANSFER);
  ADC_CommonInitStruct.CommonClock = LL_ADC_CLOCK_ASYNC_DIV2;
  ADC_CommonInitStruct.Multimode = LL_ADC_MULTI_INDEPENDENT;
  LL_ADC_CommonInit(__LL_ADC_COMMON_INSTANCE(ADC1), &ADC_CommonInitStruct);

  /* Disable ADC deep power down (enabled by default after reset state) */
  LL_ADC_DisableDeepPowerDown(ADC1);
  /* Enable ADC internal voltage regulator */
  LL_ADC_EnableInternalRegulator(ADC1);
  /* Delay for ADC internal voltage regulator stabilization. */
  /* Compute number of CPU cycles to wait for, from delay in us. */
  /* Note: Variable divided by 2 to compensate partially */
  /* CPU processing cycles (depends on compilation optimization). */
  /* Note: If system core clock frequency is below 200kHz, wait time */
  /* is only a few CPU processing cycles. */
  __IO uint32_t wait_loop_index;
  wait_loop_index = ((LL_ADC_DELAY_INTERNAL_REGUL_STAB_US * (SystemCoreClock / (100000 * 2))) / 10);
  while(wait_loop_index != 0)
  {
    wait_loop_index--;
  }

  /** Configure Regular Channel
  */
  LL_ADC_REG_SetSequencerRanks(ADC1, LL_ADC_REG_RANK_1, LL_ADC_CHANNEL_0);
  LL_ADC_SetChannelSamplingTime(ADC1, LL_ADC_CHANNEL_0, LL_ADC_SAMPLINGTIME_1CYCLE_5);
  LL_ADC_SetChannelSingleDiff(ADC1, LL_ADC_CHANNEL_0, LL_ADC_SINGLE_ENDED);
  LL_ADC_SetChannelPreselection(ADC1, LL_ADC_CHANNEL_0);

  /** Configure Regular Channel
  */
  LL_ADC_REG_SetSequencerRanks(ADC1, LL_ADC_REG_RANK_2, LL_ADC_CHANNEL_1);
  LL_ADC_SetChannelSamplingTime(ADC1, LL_ADC_CHANNEL_1, LL_ADC_SAMPLINGTIME_1CYCLE_5);
  LL_ADC_SetChannelSingleDiff(ADC1, LL_ADC_CHANNEL_1, LL_ADC_SINGLE_ENDED);
  LL_ADC_SetChannelPreselection(ADC1, LL_ADC_CHANNEL_1);

  /** Configure Regular Channel
  */
  LL_ADC_REG_SetSequencerRanks(ADC1, LL_ADC_REG_RANK_3, LL_ADC_CHANNEL_3);
  LL_ADC_SetChannelSamplingTime(ADC1, LL_ADC_CHANNEL_3, LL_ADC_SAMPLINGTIME_1CYCLE_5);
  LL_ADC_SetChannelSingleDiff(ADC1, LL_ADC_CHANNEL_3, LL_ADC_SINGLE_ENDED);
  LL_ADC_SetChannelPreselection(ADC1, LL_ADC_CHANNEL_3);
  /* USER CODE BEGIN ADC1_Init 2 */

  LL_ADC_Enable(ADC1);
  while (!LL_ADC_IsActiveFlag_ADRDY(ADC1));
  /* USER CODE END ADC1_Init 2 */

}

static void MX_ADC2_Init(void)
{

  LL_ADC_InitTypeDef ADC_InitStruct = {0};
  LL_ADC_REG_InitTypeDef ADC_REG_InitStruct = {0};

  LL_GPIO_InitTypeDef GPIO_InitStruct = {0};

  /* Peripheral clock enable */
  LL_AHB1_GRP1_EnableClock(LL_AHB1_GRP1_PERIPH_ADC12);

  LL_AHB4_GRP1_EnableClock(LL_AHB4_GRP1_PERIPH_GPIOC);
  /**ADC2 GPIO Configuration
  PC4   ------> ADC2_INP4
  */
  GPIO_InitStruct.Pin = LL_GPIO_PIN_4;
  GPIO_InitStruct.Mode = LL_GPIO_MODE_ANALOG;
  GPIO_InitStruct.Pull = LL_GPIO_PULL_NO;
  LL_GPIO_Init(GPIOC, &GPIO_InitStruct);

  /** Common config
  */
  LL_ADC_SetOverSamplingScope(ADC2, LL_ADC_OVS_DISABLE);
  ADC_InitStruct.Resolution = LL_ADC_RESOLUTION_16B;
  ADC_InitStruct.LowPowerMode = LL_ADC_LP_MODE_NONE;
  ADC_InitStruct.LeftBitShift = LL_ADC_LEFT_BIT_SHIFT_NONE;
  LL_ADC_Init(ADC2, &ADC_InitStruct);
  ADC_REG_InitStruct.TriggerSource = LL_ADC_REG_TRIG_SOFTWARE;
  ADC_REG_InitStruct.SequencerLength = LL_ADC_REG_SEQ_SCAN_DISABLE;
  ADC_REG_InitStruct.SequencerDiscont = DISABLE;
  ADC_REG_InitStruct.ContinuousMode = LL_ADC_REG_CONV_CONTINUOUS;
  ADC_REG_InitStruct.Overrun = LL_ADC_REG_OVR_DATA_OVERWRITTEN;
  LL_ADC_REG_Init(ADC2, &ADC_REG_InitStruct);
  LL_ADC_REG_SetDataTransferMode(ADC2, LL_ADC_REG_DR_TRANSFER);

  /* Disable ADC deep power down (enabled by default after reset state) */
  LL_ADC_DisableDeepPowerDown(ADC2);
  /* Enable ADC internal voltage regulator */
  LL_ADC_EnableInternalRegulator(ADC2);
  /* Delay for ADC internal voltage regulator stabilization. */
  /* Compute number of CPU cycles to wait for, from delay in us. */
  /* Note: Variable divided by 2 to compensate partially */
  /* CPU processing cycles (depends on compilation optimization). */
  /* Note: If system core clock frequency is below 200kHz, wait time */
  /* is only a few CPU processing cycles. */
  __IO uint32_t wait_loop_index;
  wait_loop_index = ((LL_ADC_DELAY_INTERNAL_REGUL_STAB_US * (SystemCoreClock / (100000 * 2))) / 10);
  while(wait_loop_index != 0)
  {
    wait_loop_index--;
  }

  /** Configure Regular Channel
  */
  LL_ADC_REG_SetSequencerRanks(ADC2, LL_ADC_REG_RANK_1, LL_ADC_CHANNEL_4);
  LL_ADC_SetChannelSamplingTime(ADC2, LL_ADC_CHANNEL_4, LL_ADC_SAMPLINGTIME_1CYCLE_5);
  LL_ADC_SetChannelSingleDiff(ADC2, LL_ADC_CHANNEL_4, LL_ADC_SINGLE_ENDED);
  LL_ADC_SetChannelPreselection(ADC2, LL_ADC_CHANNEL_4);
  /* USER CODE BEGIN ADC2_Init 2 */
  LL_ADC_Enable(ADC2);
  while (!LL_ADC_IsActiveFlag_ADRDY(ADC2));
  /* USER CODE END ADC2_Init 2 */

}

static void MX_FDCAN2_Init(void)
{

  hfdcan2.Instance = FDCAN2;
  hfdcan2.Init.FrameFormat = FDCAN_FRAME_CLASSIC;
  hfdcan2.Init.Mode = FDCAN_MODE_NORMAL;
  hfdcan2.Init.AutoRetransmission = DISABLE;
  hfdcan2.Init.TransmitPause = DISABLE;
  hfdcan2.Init.ProtocolException = DISABLE;
  hfdcan2.Init.NominalPrescaler = 10;
  hfdcan2.Init.NominalSyncJumpWidth = 1;
  hfdcan2.Init.NominalTimeSeg1 = 8;
  hfdcan2.Init.NominalTimeSeg2 = 1;
  hfdcan2.Init.DataPrescaler = 1;
  hfdcan2.Init.DataSyncJumpWidth = 1;
  hfdcan2.Init.DataTimeSeg1 = 1;
  hfdcan2.Init.DataTimeSeg2 = 1;
  hfdcan2.Init.MessageRAMOffset = 0;
  hfdcan2.Init.StdFiltersNbr = 0;
  hfdcan2.Init.ExtFiltersNbr = 1;
  hfdcan2.Init.RxFifo0ElmtsNbr = 8;
  hfdcan2.Init.RxFifo0ElmtSize = FDCAN_DATA_BYTES_8;
  hfdcan2.Init.RxFifo1ElmtsNbr = 0;
  hfdcan2.Init.RxFifo1ElmtSize = FDCAN_DATA_BYTES_8;
  hfdcan2.Init.RxBuffersNbr = 0;
  hfdcan2.Init.RxBufferSize = FDCAN_DATA_BYTES_8;
  hfdcan2.Init.TxEventsNbr = 0;
  hfdcan2.Init.TxBuffersNbr = 0;
  hfdcan2.Init.TxFifoQueueElmtsNbr = 8;
  hfdcan2.Init.TxFifoQueueMode = FDCAN_TX_FIFO_OPERATION;
  hfdcan2.Init.TxElmtSize = FDCAN_DATA_BYTES_8;
  if (HAL_FDCAN_Init(&hfdcan2) != HAL_OK)
  {
    Error_Handler();
  }

}

static void MX_I2C1_Init(void)
{

  LL_I2C_InitTypeDef I2C_InitStruct = {0};

  LL_GPIO_InitTypeDef GPIO_InitStruct = {0};
  RCC_PeriphCLKInitTypeDef PeriphClkInitStruct = {0};

  /** Initializes the peripherals clock
  */
  PeriphClkInitStruct.PeriphClockSelection = RCC_PERIPHCLK_I2C1;
  PeriphClkInitStruct.I2c123ClockSelection = RCC_I2C123CLKSOURCE_D2PCLK1;
  if (HAL_RCCEx_PeriphCLKConfig(&PeriphClkInitStruct) != HAL_OK)
  {
    Error_Handler();
  }

  LL_AHB4_GRP1_EnableClock(LL_AHB4_GRP1_PERIPH_GPIOB);
  /**I2C1 GPIO Configuration
  PB6   ------> I2C1_SCL
  PB7   ------> I2C1_SDA
  */
  GPIO_InitStruct.Pin = LL_GPIO_PIN_6|LL_GPIO_PIN_7;
  GPIO_InitStruct.Mode = LL_GPIO_MODE_ALTERNATE;
  GPIO_InitStruct.Speed = LL_GPIO_SPEED_FREQ_LOW;
  GPIO_InitStruct.OutputType = LL_GPIO_OUTPUT_OPENDRAIN;
  GPIO_InitStruct.Pull = LL_GPIO_PULL_NO;
  GPIO_InitStruct.Alternate = LL_GPIO_AF_4;
  LL_GPIO_Init(GPIOB, &GPIO_InitStruct);

  /* Peripheral clock enable */
  LL_APB1_GRP1_EnableClock(LL_APB1_GRP1_PERIPH_I2C1);

  /** I2C Initialization
  */
  LL_I2C_EnableAutoEndMode(I2C1);
  LL_I2C_SetOwnAddress2(I2C1, 0, LL_I2C_OWNADDRESS2_NOMASK);
  LL_I2C_DisableOwnAddress2(I2C1);
  LL_I2C_DisableGeneralCall(I2C1);
  LL_I2C_EnableClockStretching(I2C1);
  I2C_InitStruct.PeripheralMode = LL_I2C_MODE_I2C;
  I2C_InitStruct.Timing = 0x00909FCE;
  I2C_InitStruct.AnalogFilter = LL_I2C_ANALOGFILTER_ENABLE;
  I2C_InitStruct.DigitalFilter = 0;
  I2C_InitStruct.OwnAddress1 = 0;
  I2C_InitStruct.TypeAcknowledge = LL_I2C_ACK;
  I2C_InitStruct.OwnAddrSize = LL_I2C_OWNADDRESS1_7BIT;
  LL_I2C_Init(I2C1, &I2C_InitStruct);

}

static void MX_SDMMC1_MMC_Init(void)
{

  hmmc1.Instance = SDMMC1;
  hmmc1.Init.ClockEdge = SDMMC_CLOCK_EDGE_RISING;
  hmmc1.Init.ClockPowerSave = SDMMC_CLOCK_POWER_SAVE_DISABLE;
  hmmc1.Init.BusWide = SDMMC_BUS_WIDE_8B;
  hmmc1.Init.HardwareFlowControl = SDMMC_HARDWARE_FLOW_CONTROL_DISABLE;
  hmmc1.Init.ClockDiv = 8;
  if (HAL_MMC_Init(&hmmc1) != HAL_OK)
  {
    Error_Handler();
  }
  /* USER CODE BEGIN SDMMC1_Init 2 */
	FRESULT res;
	uint8_t work[FF_MAX_SS];
	extern FATFS fs;

	  res = f_mount(&fs, "", 1);

	  if (res == FR_NO_FILESYSTEM) {
//	      embeddedCliPrint(get_COMM_UART_CliPointer(), "No filesystem found. Formatting eMMC...\r\n");

	      res = f_mkfs("", NULL, work, sizeof(work));
	      if (res == FR_OK) {
//	          embeddedCliPrint(get_COMM_UART_CliPointer(), "Format success. Mounting...\r\n");
	          res = f_mount(&fs, "", 1);
	          if (res != FR_OK){
//	              embeddedCliPrint(get_COMM_UART_CliPointer(), "f_mount after format failed\r\n");
	          }
	      } else {
//	          embeddedCliPrint(get_COMM_UART_CliPointer(), "f_mkfs failed\r\n");
	      }
	  }
	  else if (res == FR_OK) {
//	      embeddedCliPrint(get_COMM_UART_CliPointer(), "eMMC mounted successfully.\r\n");
	  }
	  else {
	      char msg[64];
	      snprintf(msg, sizeof(msg), "f_mount error: %d\r\n", res);
	      embeddedCliPrint(get_COMM_UART_CliPointer(), msg);
	  }

  /* USER CODE END SDMMC1_Init 2 */

}

static void MX_SPI1_Init(void)
{

  LL_SPI_InitTypeDef SPI_InitStruct = {0};

  LL_GPIO_InitTypeDef GPIO_InitStruct = {0};
  RCC_PeriphCLKInitTypeDef PeriphClkInitStruct = {0};

  /** Initializes the peripherals clock
  */
  PeriphClkInitStruct.PeriphClockSelection = RCC_PERIPHCLK_SPI1;
  PeriphClkInitStruct.Spi123ClockSelection = RCC_SPI123CLKSOURCE_PLL;
  if (HAL_RCCEx_PeriphCLKConfig(&PeriphClkInitStruct) != HAL_OK)
  {
    Error_Handler();
  }

  /* Peripheral clock enable */
  LL_APB2_GRP1_EnableClock(LL_APB2_GRP1_PERIPH_SPI1);

  LL_AHB4_GRP1_EnableClock(LL_AHB4_GRP1_PERIPH_GPIOG);
  LL_AHB4_GRP1_EnableClock(LL_AHB4_GRP1_PERIPH_GPIOD);
  /**SPI1 GPIO Configuration
  PG11   ------> SPI1_SCK
  PD7   ------> SPI1_MOSI
  */
  GPIO_InitStruct.Pin = LVDS_SCK_Pin;
  GPIO_InitStruct.Mode = LL_GPIO_MODE_ALTERNATE;
  GPIO_InitStruct.Speed = LL_GPIO_SPEED_FREQ_LOW;
  GPIO_InitStruct.OutputType = LL_GPIO_OUTPUT_PUSHPULL;
  GPIO_InitStruct.Pull = LL_GPIO_PULL_NO;
  GPIO_InitStruct.Alternate = LL_GPIO_AF_5;
  LL_GPIO_Init(LVDS_SCK_GPIO_Port, &GPIO_InitStruct);

  GPIO_InitStruct.Pin = LVDS_MOSI_Pin;
  GPIO_InitStruct.Mode = LL_GPIO_MODE_ALTERNATE;
  GPIO_InitStruct.Speed = LL_GPIO_SPEED_FREQ_LOW;
  GPIO_InitStruct.OutputType = LL_GPIO_OUTPUT_PUSHPULL;
  GPIO_InitStruct.Pull = LL_GPIO_PULL_NO;
  GPIO_InitStruct.Alternate = LL_GPIO_AF_5;
  LL_GPIO_Init(LVDS_MOSI_GPIO_Port, &GPIO_InitStruct);

  /* SPI1 parameter configuration*/
  SPI_InitStruct.TransferDirection = LL_SPI_HALF_DUPLEX_TX;
  SPI_InitStruct.Mode = LL_SPI_MODE_MASTER;
  SPI_InitStruct.DataWidth = LL_SPI_DATAWIDTH_8BIT;
  SPI_InitStruct.ClockPolarity = LL_SPI_POLARITY_LOW;
  SPI_InitStruct.ClockPhase = LL_SPI_PHASE_1EDGE;
  SPI_InitStruct.NSS = LL_SPI_NSS_SOFT;
  SPI_InitStruct.BaudRate = LL_SPI_BAUDRATEPRESCALER_DIV64;
  SPI_InitStruct.BitOrder = LL_SPI_MSB_FIRST;
  SPI_InitStruct.CRCCalculation = LL_SPI_CRCCALCULATION_DISABLE;
  SPI_InitStruct.CRCPoly = 0x0;
  LL_SPI_Init(SPI1, &SPI_InitStruct);
  LL_SPI_SetStandard(SPI1, LL_SPI_PROTOCOL_MOTOROLA);
  LL_SPI_SetFIFOThreshold(SPI1, LL_SPI_FIFO_TH_01DATA);
  LL_SPI_EnableNSSPulseMgt(SPI1);
  /* USER CODE BEGIN SPI1_Init 2 */
  LL_SPI_Enable(SPI1);
  /* USER CODE END SPI1_Init 2 */

}

static void MX_SPI2_Init(void)
{

  LL_SPI_InitTypeDef SPI_InitStruct = {0};

  LL_GPIO_InitTypeDef GPIO_InitStruct = {0};
  RCC_PeriphCLKInitTypeDef PeriphClkInitStruct = {0};

  /** Initializes the peripherals clock
  */
  PeriphClkInitStruct.PeriphClockSelection = RCC_PERIPHCLK_SPI2;
  PeriphClkInitStruct.Spi123ClockSelection = RCC_SPI123CLKSOURCE_PLL;
  if (HAL_RCCEx_PeriphCLKConfig(&PeriphClkInitStruct) != HAL_OK)
  {
    Error_Handler();
  }

  /* Peripheral clock enable */
  LL_APB1_GRP1_EnableClock(LL_APB1_GRP1_PERIPH_SPI2);

  LL_AHB4_GRP1_EnableClock(LL_AHB4_GRP1_PERIPH_GPIOD);
  LL_AHB4_GRP1_EnableClock(LL_AHB4_GRP1_PERIPH_GPIOC);
  /**SPI2 GPIO Configuration
  PD3   ------> SPI2_SCK
  PC1   ------> SPI2_MOSI
  PC2   ------> SPI2_MISO
  */
  GPIO_InitStruct.Pin = SRAM_SCK_Pin;
  GPIO_InitStruct.Mode = LL_GPIO_MODE_ALTERNATE;
  GPIO_InitStruct.Speed = LL_GPIO_SPEED_FREQ_LOW;
  GPIO_InitStruct.OutputType = LL_GPIO_OUTPUT_PUSHPULL;
  GPIO_InitStruct.Pull = LL_GPIO_PULL_NO;
  GPIO_InitStruct.Alternate = LL_GPIO_AF_5;
  LL_GPIO_Init(SRAM_SCK_GPIO_Port, &GPIO_InitStruct);

  GPIO_InitStruct.Pin = SRAM_MOSI_Pin|SRAM_MISO_Pin;
  GPIO_InitStruct.Mode = LL_GPIO_MODE_ALTERNATE;
  GPIO_InitStruct.Speed = LL_GPIO_SPEED_FREQ_LOW;
  GPIO_InitStruct.OutputType = LL_GPIO_OUTPUT_PUSHPULL;
  GPIO_InitStruct.Pull = LL_GPIO_PULL_NO;
  GPIO_InitStruct.Alternate = LL_GPIO_AF_5;
  LL_GPIO_Init(GPIOC, &GPIO_InitStruct);

  /* SPI2 parameter configuration*/
  SPI_InitStruct.TransferDirection = LL_SPI_FULL_DUPLEX;
  SPI_InitStruct.Mode = LL_SPI_MODE_MASTER;
  SPI_InitStruct.DataWidth = LL_SPI_DATAWIDTH_8BIT;
  SPI_InitStruct.ClockPolarity = LL_SPI_POLARITY_LOW;
  SPI_InitStruct.ClockPhase = LL_SPI_PHASE_1EDGE;
  SPI_InitStruct.NSS = LL_SPI_NSS_SOFT;
  SPI_InitStruct.BaudRate = LL_SPI_BAUDRATEPRESCALER_DIV64;
  SPI_InitStruct.BitOrder = LL_SPI_MSB_FIRST;
  SPI_InitStruct.CRCCalculation = LL_SPI_CRCCALCULATION_DISABLE;
  SPI_InitStruct.CRCPoly = 0x0;
  LL_SPI_Init(SPI2, &SPI_InitStruct);
  LL_SPI_SetStandard(SPI2, LL_SPI_PROTOCOL_MOTOROLA);
  LL_SPI_SetFIFOThreshold(SPI2, LL_SPI_FIFO_TH_01DATA);
  LL_SPI_EnableNSSPulseMgt(SPI2);
  /* USER CODE BEGIN SPI2_Init 2 */
  LL_SPI_Enable(SPI2);
  /* USER CODE END SPI2_Init 2 */

}

static void MX_UART4_Init(void)
{

  LL_USART_InitTypeDef UART_InitStruct = {0};

  LL_GPIO_InitTypeDef GPIO_InitStruct = {0};
  RCC_PeriphCLKInitTypeDef PeriphClkInitStruct = {0};

  /** Initializes the peripherals clock
  */
  PeriphClkInitStruct.PeriphClockSelection = RCC_PERIPHCLK_UART4;
  PeriphClkInitStruct.Usart234578ClockSelection = RCC_USART234578CLKSOURCE_D2PCLK1;
  if (HAL_RCCEx_PeriphCLKConfig(&PeriphClkInitStruct) != HAL_OK)
  {
    Error_Handler();
  }

  /* Peripheral clock enable */
  LL_APB1_GRP1_EnableClock(LL_APB1_GRP1_PERIPH_UART4);

  LL_AHB4_GRP1_EnableClock(LL_AHB4_GRP1_PERIPH_GPIOA);
  /**UART4 GPIO Configuration
  PA1   ------> UART4_RX
  PA0   ------> UART4_TX
  */
  GPIO_InitStruct.Pin = LL_GPIO_PIN_1|LL_GPIO_PIN_0;
  GPIO_InitStruct.Mode = LL_GPIO_MODE_ALTERNATE;
  GPIO_InitStruct.Speed = LL_GPIO_SPEED_FREQ_LOW;
  GPIO_InitStruct.OutputType = LL_GPIO_OUTPUT_PUSHPULL;
  GPIO_InitStruct.Pull = LL_GPIO_PULL_NO;
  GPIO_InitStruct.Alternate = LL_GPIO_AF_8;
  LL_GPIO_Init(GPIOA, &GPIO_InitStruct);

  /* UART4 interrupt Init */
  NVIC_SetPriority(UART4_IRQn, NVIC_EncodePriority(NVIC_GetPriorityGrouping(),0, 0));
  NVIC_EnableIRQ(UART4_IRQn);

  UART_InitStruct.PrescalerValue = LL_USART_PRESCALER_DIV1;
  UART_InitStruct.BaudRate = 115200;
  UART_InitStruct.DataWidth = LL_USART_DATAWIDTH_8B;
  UART_InitStruct.StopBits = LL_USART_STOPBITS_1;
  UART_InitStruct.Parity = LL_USART_PARITY_NONE;
  UART_InitStruct.TransferDirection = LL_USART_DIRECTION_TX_RX;
  UART_InitStruct.HardwareFlowControl = LL_USART_HWCONTROL_NONE;
  UART_InitStruct.OverSampling = LL_USART_OVERSAMPLING_16;
  LL_USART_Init(UART4, &UART_InitStruct);
  LL_USART_DisableFIFO(UART4);
  LL_USART_SetTXFIFOThreshold(UART4, LL_USART_FIFOTHRESHOLD_1_8);
  LL_USART_SetRXFIFOThreshold(UART4, LL_USART_FIFOTHRESHOLD_1_8);
  LL_USART_ConfigAsyncMode(UART4);

  LL_USART_Enable(UART4);

  /* Polling UART4 initialisation */
  while((!(LL_USART_IsActiveFlag_TEACK(UART4))) || (!(LL_USART_IsActiveFlag_REACK(UART4))))
  {
  }

}

static void MX_GPIO_Init(void)
{
  LL_GPIO_InitTypeDef GPIO_InitStruct = {0};

  /* GPIO Ports Clock Enable */
  LL_AHB4_GRP1_EnableClock(LL_AHB4_GRP1_PERIPH_GPIOC);
  LL_AHB4_GRP1_EnableClock(LL_AHB4_GRP1_PERIPH_GPIOB);
  LL_AHB4_GRP1_EnableClock(LL_AHB4_GRP1_PERIPH_GPIOG);
  LL_AHB4_GRP1_EnableClock(LL_AHB4_GRP1_PERIPH_GPIOD);
  LL_AHB4_GRP1_EnableClock(LL_AHB4_GRP1_PERIPH_GPIOA);

  /**/
  LL_GPIO_SetOutputPin(WD_DONE_GPIO_Port, WD_DONE_Pin);

  /**/
  LL_GPIO_ResetOutputPin(GPIOA, LED_B_Pin|LED_G_Pin);

  /**/
  GPIO_InitStruct.Pin = WD_DONE_Pin;
  GPIO_InitStruct.Mode = LL_GPIO_MODE_OUTPUT;
  GPIO_InitStruct.Speed = LL_GPIO_SPEED_FREQ_LOW;
  GPIO_InitStruct.OutputType = LL_GPIO_OUTPUT_PUSHPULL;
  GPIO_InitStruct.Pull = LL_GPIO_PULL_NO;
  LL_GPIO_Init(WD_DONE_GPIO_Port, &GPIO_InitStruct);

  /**/
  GPIO_InitStruct.Pin = LED_B_Pin|LED_G_Pin;
  GPIO_InitStruct.Mode = LL_GPIO_MODE_OUTPUT;
  GPIO_InitStruct.Speed = LL_GPIO_SPEED_FREQ_LOW;
  GPIO_InitStruct.OutputType = LL_GPIO_OUTPUT_PUSHPULL;
  GPIO_InitStruct.Pull = LL_GPIO_PULL_NO;
  LL_GPIO_Init(GPIOA, &GPIO_InitStruct);

}

void HAL_TIM_PeriodElapsedCallback(TIM_HandleTypeDef *htim)
{
  if (htim->Instance == TIM1)
  {
    HAL_IncTick();
  }
}

void Error_Handler(void)
{
  __disable_irq();
  while (1)
  {
  }
}
